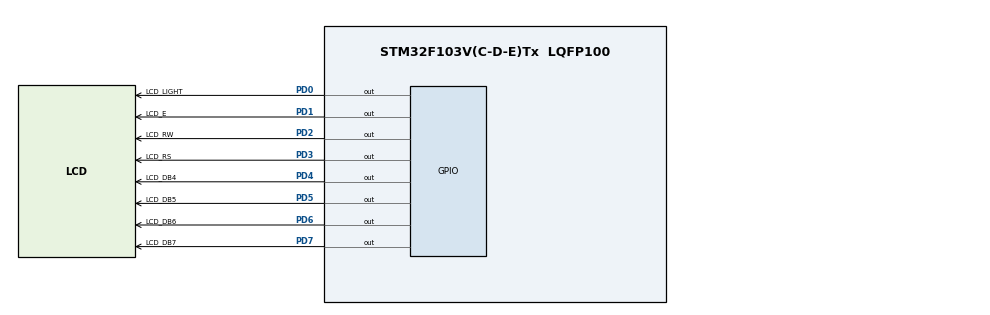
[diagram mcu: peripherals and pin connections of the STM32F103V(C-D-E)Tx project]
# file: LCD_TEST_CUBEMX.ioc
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Mcu.Family=STM32F1
Mcu.Name=STM32F103V(C-D-E)Tx
Mcu.Package=LQFP100
NVIC.PriorityGroup=NVIC_PRIORITYGROUP_4
OSC_IN.Mode=HSE-External-Oscillator
OSC_IN.Signal=RCC_OSC_IN
OSC_OUT.Mode=HSE-External-Oscillator
OSC_OUT.Signal=RCC_OSC_OUT
PA13.Mode=Serial_Wire
PA13.Signal=SYS_JTMS-SWDIO
PA14.Mode=Serial_Wire
PA14.Signal=SYS_JTCK-SWCLK
PD0.GPIO_Label=LCD_LIGHT
PD0.GPIO_Speed=GPIO_SPEED_FREQ_HIGH
PD0.Signal=GPIO_Output
PD1.GPIO_Label=LCD_E
PD1.GPIO_Speed=GPIO_SPEED_FREQ_HIGH
PD1.Signal=GPIO_Output
PD2.GPIO_Label=LCD_RW
PD2.GPIO_Speed=GPIO_SPEED_FREQ_HIGH
PD2.Signal=GPIO_Output
PD3.GPIO_Label=LCD_RS
PD3.GPIO_Speed=GPIO_SPEED_FREQ_HIGH
PD3.Signal=GPIO_Output
PD4.GPIO_Label=LCD_DB4
PD4.GPIO_Speed=GPIO_SPEED_FREQ_HIGH
PD4.Signal=GPIO_Output
PD5.GPIO_Label=LCD_DB5
PD5.GPIO_Speed=GPIO_SPEED_FREQ_HIGH
PD5.Signal=GPIO_Output
PD6.GPIO_Label=LCD_DB6
PD6.GPIO_Speed=GPIO_SPEED_FREQ_HIGH
PD6.Signal=GPIO_Output
PD7.GPIO_Label=LCD_DB7
PD7.GPIO_Speed=GPIO_SPEED_FREQ_HIGH
PD7.Signal=GPIO_Output
ProjectManager.HeapSize=0x200
ProjectManager.StackSize=0x400
ProjectManager.TargetToolchain=Makefile
RCC.APB1Freq_Value=8000000
RCC.APB2Freq_Value=8000000
board=custom

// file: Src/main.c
/* USER CODE BEGIN Header */
/**
  ******************************************************************************
  * @file           : main.c
  * @brief          : Main program body
  ******************************************************************************
  * @attention
  *
  * <h2><center>&copy; Copyright (c) 2019 STMicroelectronics.
  * All rights reserved.</center></h2>
  *
  * This software component is licensed by ST under BSD 3-Clause license,
  * the "License"; You may not use this file except in compliance with the
  * License. You may obtain a copy of the License at:
  *                        opensource.org/licenses/BSD-3-Clause
  *
  ******************************************************************************
  */
/* USER CODE END Header */

#include "main.h"
/* USER CODE BEGIN Includes */
#include "lcd.h"
/* USER CODE END Includes */

void SystemClock_Config(void);
static void MX_GPIO_Init(void);

int main(void)
{

  /* MCU Configuration--------------------------------------------------------*/

  /* Reset of all peripherals, Initializes the Flash interface and the Systick. */
  HAL_Init();

  /* Configure the system clock */
  SystemClock_Config();

  /* Initialize all configured peripherals */
  MX_GPIO_Init();
  /* USER CODE BEGIN 2 */
  LCD_Init();
  LCD_SetPos(0, 0);
  LCD_String("LCD_TEST");
  LCD_SetPos(1, 1);
  LCD_String("STM32F103");
  LCD_SetPos(2, 2);
  LCD_String("Motor_Control");
  LCD_SetPos(3, 3);
  LCD_String("Continue");
  /* USER CODE END 2 */

  /* Infinite loop */
  while (1)
  {

  }
}

void SystemClock_Config(void)
{
  RCC_OscInitTypeDef RCC_OscInitStruct = {0};
  RCC_ClkInitTypeDef RCC_ClkInitStruct = {0};

  /** Initializes the CPU, AHB and APB busses clocks
  */
  RCC_OscInitStruct.OscillatorType = RCC_OSCILLATORTYPE_HSI;
  RCC_OscInitStruct.HSIState = RCC_HSI_ON;
  RCC_OscInitStruct.HSICalibrationValue = RCC_HSICALIBRATION_DEFAULT;
  RCC_OscInitStruct.PLL.PLLState = RCC_PLL_NONE;
  if (HAL_RCC_OscConfig(&RCC_OscInitStruct) != HAL_OK)
  {
    Error_Handler();
  }
  /** Initializes the CPU, AHB and APB busses clocks
  */
  RCC_ClkInitStruct.ClockType = RCC_CLOCKTYPE_HCLK|RCC_CLOCKTYPE_SYSCLK
                              |RCC_CLOCKTYPE_PCLK1|RCC_CLOCKTYPE_PCLK2;
  RCC_ClkInitStruct.SYSCLKSource = RCC_SYSCLKSOURCE_HSI;
  RCC_ClkInitStruct.AHBCLKDivider = RCC_SYSCLK_DIV1;
  RCC_ClkInitStruct.APB1CLKDivider = RCC_HCLK_DIV1;
  RCC_ClkInitStruct.APB2CLKDivider = RCC_HCLK_DIV1;

  if (HAL_RCC_ClockConfig(&RCC_ClkInitStruct, FLASH_LATENCY_0) != HAL_OK)
  {
    Error_Handler();
  }
}

static void MX_GPIO_Init(void)
{
  GPIO_InitTypeDef GPIO_InitStruct = {0};

  /* GPIO Ports Clock Enable */
  __HAL_RCC_GPIOA_CLK_ENABLE();
  __HAL_RCC_GPIOD_CLK_ENABLE();

  /*Configure GPIO pin Output Level */
  HAL_GPIO_WritePin(GPIOD, LCD_LIGHT_Pin|LCD_E_Pin|LCD_RW_Pin|LCD_RS_Pin
                          |LCD_DB4_Pin|LCD_DB5_Pin|LCD_DB6_Pin|LCD_DB7_Pin, GPIO_PIN_RESET);

  /*Configure GPIO pins : LCD_LIGHT_Pin LCD_E_Pin LCD_RW_Pin LCD_RS_Pin
                           LCD_DB4_Pin LCD_DB5_Pin LCD_DB6_Pin LCD_DB7_Pin */
  GPIO_InitStruct.Pin = LCD_LIGHT_Pin|LCD_E_Pin|LCD_RW_Pin|LCD_RS_Pin
                          |LCD_DB4_Pin|LCD_DB5_Pin|LCD_DB6_Pin|LCD_DB7_Pin;
  GPIO_InitStruct.Mode = GPIO_MODE_OUTPUT_PP;
  GPIO_InitStruct.Pull = GPIO_NOPULL;
  GPIO_InitStruct.Speed = GPIO_SPEED_FREQ_HIGH;
  HAL_GPIO_Init(GPIOD, &GPIO_InitStruct);

}

void Error_Handler(void)
{
}

/************************ (C) COPYRIGHT STMicroelectronics *****END OF FILE****/
